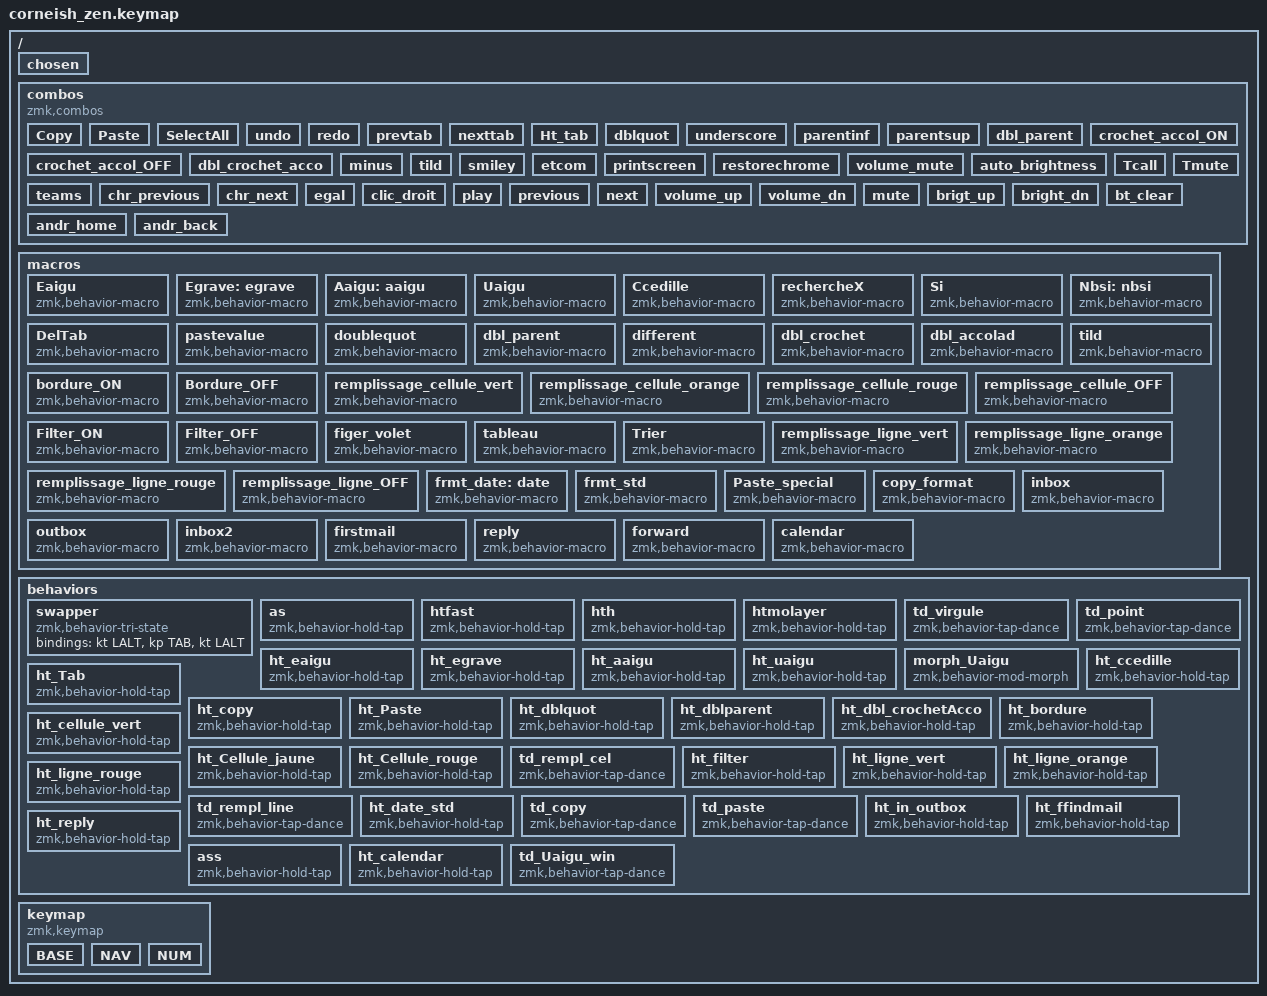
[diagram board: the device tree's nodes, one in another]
#include <behaviors.dtsi>
#include <dt-bindings/zmk/bt.h>
#include <dt-bindings/zmk/keys.h>

/ {
    chosen {
        zmk,physical-layout = &foostan_corne_6col_layout;

        // zmk,physical-layout = &foostan_corne_5col_layout;
    };
};

/ {
    combos {
        compatible = "zmk,combos";

        //-----------------------------------------------------------------
        //-----------------------------------------------------------------

        Copy {
            bindings = <&td_copy>;
            key-positions = <14 15>;
            timeout-ms = <20>;
        };

        Paste {
            bindings = <&td_paste>;
            key-positions = <15 16>;
            timeout-ms = <20>;
        };

        SelectAll {
            bindings = <&kp LC(Q)>;
            key-positions = <14 15 16>;
        };

        undo {
            bindings = <&kp LC(W)>;
            key-positions = <2 3>;
            timeout-ms = <20>;
        };

        redo {
            bindings = <&kp LC(Y)>;
            key-positions = <3 4>;
            timeout-ms = <20>;
        };

        prevtab {
            bindings = <&kp LC(PAGE_UP)>;
            key-positions = <26 27>;
            layers = <0 3>;
        };

        nexttab {
            bindings = <&kp LC(PAGE_DOWN)>;
            key-positions = <27 28>;
            layers = <0 3>;
        };

        Ht_tab {
            bindings = <&ht_Tab 0 LS(F11)>;
            key-positions = <26 27 28>;
            layers = <0>;
        };

        dblquot {
            bindings = <&ht_dblquot 0 N3>;
            key-positions = <16 17>;
        };

        underscore {
            bindings = <&kp N8>;
            key-positions = <28 29>;
        };

        parentinf {
            bindings = <&hth NUBS N5>;
            key-positions = <19 20>;
            timeout-ms = <15>;
        };

        parentsup {
            bindings = <&hth LS(NUBS) MINUS>;
            key-positions = <20 21>;
        };

        dbl_parent {
            bindings = <&ht_dblparent 0 0>;
            key-positions = <19 20 21>;
        };

        crochet_accol_ON {
            bindings = <&hth RA(N4) RA(N5)>;
            key-positions = <31 32>;
            layers = <0>;
        };

        crochet_accol_OFF {
            bindings = <&hth RA(EQUAL) RA(MINUS)>;
            key-positions = <32 33>;
        };

        dbl_crochet_acco {
            bindings = <&ht_dbl_crochetAcco 0 0>;
            key-positions = <31 32 33>;
            layers = <0>;
        };

        minus {
            bindings = <&kp N6>;
            key-positions = <18 19>;
        };

        tild {
            bindings = <&tild>;
            key-positions = <5 6>;
        };

        smiley {
            bindings = <&kp LG(COMMA)>;
            key-positions = <17 18>;
        };

        etcom {
            bindings = <&kp N1>;
            key-positions = <29 30>;
        };

        printscreen {
            bindings = <&hth LG(N9) LS(LG(S))>;
            key-positions = <4 5>;
        };

        restorechrome {
            bindings = <&kp LS(LC(T))>;
            key-positions = <26 27 28>;
            layers = <1 3>;
        };

        volume_mute {
            bindings = <&kp C_MUTE>;
            key-positions = <10 11>;
            layers = <1>;
        };

        auto_brightness {
            bindings = <&kp C_BRIGHTNESS_AUTO>;
            key-positions = <22 23>;
            layers = <1>;
        };

        Tcall {
            bindings = <&hth LC(LS(H)) LS(LC(S))>;
            key-positions = <38 39>;
        };

        Tmute {
            bindings = <&kp LS(LC(SEMI))>;
            key-positions = <40 37>;
        };

        teams {
            bindings = <&kp LG(N1)>;
            key-positions = <36 41>;
        };

        chr_previous {
            bindings = <&kp LA(LEFT)>;
            key-positions = <26 27>;
            layers = <1>;
        };

        chr_next {
            bindings = <&kp LA(RIGHT)>;
            key-positions = <28 27>;
            layers = <1>;
        };

        egal {
            bindings = <&kp EQUAL>;
            key-positions = <30 31>;
        };

        clic_droit {
            bindings = <&kp K_APP>;
            key-positions = <6 7>;
        };

        play {
            bindings = <&kp C_PLAY_PAUSE>;
            key-positions = <7 8 9>;
        };

        previous {
            bindings = <&kp C_PREVIOUS>;
            key-positions = <7 8>;
        };

        next {
            bindings = <&kp C_NEXT>;
            key-positions = <8 9>;
        };

        volume_up {
            bindings = <&kp C_VOLUME_UP>;
            key-positions = <11 23>;
            layers = <0>;
        };

        volume_dn {
            bindings = <&kp C_VOLUME_DOWN>;
            key-positions = <35 23>;
            layers = <0>;
        };

        mute {
            bindings = <&kp C_MUTE>;
            key-positions = <10 11>;
        };

        brigt_up {
            bindings = <&kp C_BRIGHTNESS_INC>;
            key-positions = <12 0>;
        };

        bright_dn {
            bindings = <&kp C_BRIGHTNESS_DEC>;
            key-positions = <12 24>;
        };

        bt_clear {
            bindings = <&bt BT_CLR>;
            key-positions = <22 23>;
            layers = <1>;
        };

        andr_home {
            bindings = <&kp LG(RET)>;
            key-positions = <31 32 33>;
            layers = <1>;
        };

        andr_back {
            bindings = <&kp LG(BACKSPACE)>;
            key-positions = <31>;
            layers = <1>;
        };
    };

    macros {
    //-----------------------------------------------------------------
    //-----------------------------------------------------------------

        Eaigu: Eaigu {
            compatible = "zmk,behavior-macro";
            #binding-cells = <0>;
            bindings =
                <&macro_press>,
                <&kp LEFT_ALT>,
                <&macro_tap>,
                <&kp KP_N1 &kp KP_N4 &kp KP_N4>,
                <&macro_release>,
                <&kp LEFT_ALT>;

            label = "EAIGU";
        };

        Egrave: egrave {
            compatible = "zmk,behavior-macro";
            #binding-cells = <0>;
            bindings =
                <&macro_press>,
                <&kp LEFT_ALT>,
                <&macro_tap>,
                <&kp KP_N2 &kp KP_N1 &kp KP_N2>,
                <&macro_release>,
                <&kp LEFT_ALT>;

            label = "EGRAVE";
        };

        Aaigu: aaigu {
            compatible = "zmk,behavior-macro";
            #binding-cells = <0>;
            bindings =
                <&macro_press>,
                <&kp LEFT_ALT>,
                <&macro_tap>,
                <&kp KP_N0 &kp KP_N1 &kp KP_N9 &kp KP_N2>,
                <&macro_release>,
                <&kp LEFT_ALT>;

            label = "AAIGU";
        };

        Uaigu: Uaigu {
            compatible = "zmk,behavior-macro";
            #binding-cells = <0>;
            bindings =
                <&macro_press>,
                <&kp LEFT_ALT>,
                <&macro_tap>,
                <&kp KP_N2 &kp KP_N3 &kp KP_N5>,
                <&macro_release>,
                <&kp LEFT_ALT>;

            label = "UAIGU";
        };

        Ccedille: Ccedille {
            compatible = "zmk,behavior-macro";
            #binding-cells = <0>;
            bindings =
                <&macro_press>,
                <&kp LEFT_ALT>,
                <&macro_tap>,
                <&kp KP_N1 &kp KP_N2 &kp KP_N8>,
                <&macro_release>,
                <&kp LEFT_ALT>;

            label = "CCEDILLE";
        };

        rechercheX: rechercheX {
            compatible = "zmk,behavior-macro";
            #binding-cells = <0>;
            bindings = <&kp DEL &kp F2 &kp MINUS &kp LEFT &kp EQUAL &kp LS(R) &kp LS(E) &kp LS(C) &kp LS(H) &kp LS(E) &kp LS(R) &kp LS(C) &kp LS(H) &kp LS(E) &kp LS(X) &kp N5>;
            label = "RECHERCHEX";
        };

        Si: Si {
            compatible = "zmk,behavior-macro";
            #binding-cells = <0>;
            bindings = <&kp DEL &kp F2 &kp MINUS &kp LEFT &kp EQUAL &kp LS(S) &kp LS(I) &kp N5>;
            label = "SI";
        };

        Nbsi: nbsi {
            compatible = "zmk,behavior-macro";
            #binding-cells = <0>;
            bindings = <&kp DEL &kp F2 &kp MINUS &kp LEFT &kp EQUAL &kp LS(N) &kp LS(B) &kp LS(COMMA) &kp LS(S) &kp LS(I) &kp N5>;
            label = "NBSI";
        };

        DelTab: DelTab {
            compatible = "zmk,behavior-macro";
            #binding-cells = <0>;
            bindings = <&kp LEFT_ALT &kp L &kp U &kp S &kp F>;
            label = "DELTAB";
        };

        pastevalue: pastevalue {
            compatible = "zmk,behavior-macro";
            #binding-cells = <0>;
            bindings = <&kp LA(LC(V)) &kp V &kp RET>;
            label = "PASTEVALUE";
        };

        doublequot: doublequot {
            compatible = "zmk,behavior-macro";
            #binding-cells = <0>;
            bindings = <&kp N3 &kp N3 &kp LEFT>;
            label = "DOUBLEQUOT";
        };

        dbl_parent: dbl_parent {
            compatible = "zmk,behavior-macro";
            #binding-cells = <0>;
            bindings = <&kp N5 &kp MINUS &kp LEFT>;
            label = "DBL_PARENT";
        };

        different: different {
            compatible = "zmk,behavior-macro";
            #binding-cells = <0>;
            bindings = <&kp NUBS &kp LS(NUBS) &kp SPACE>;
            label = "DIFFERENT";
        };

        dbl_crochet: dbl_crochet {
            compatible = "zmk,behavior-macro";
            #binding-cells = <0>;
            bindings = <&kp RA(N5) &kp RA(MINUS) &kp LEFT>;
            label = "DBL_CROCHET";
        };

        dbl_accolad: dbl_accolad {
            compatible = "zmk,behavior-macro";
            #binding-cells = <0>;
            bindings = <&kp RA(N4) &kp RA(EQUAL) &kp LEFT>;
            label = "DBL_ACCOLAD";
        };

        tild: tild {
            compatible = "zmk,behavior-macro";
            #binding-cells = <0>;
            bindings = <&kp RA(N7) &kp SPACE>;
            label = "TILD";
        };

        bordure_ON: bordure_ON {
            compatible = "zmk,behavior-macro";
            #binding-cells = <0>;
            bindings = <&kp LC(Q) &kp LEFT_ALT &kp L &kp N9 &kp J &kp LEFT_ALT &kp L &kp N9 &kp Q &kp LEFT_ALT &kp L &kp B &kp B &kp E>;
            label = "BORDURE_ON";
        };

        Bordure_OFF: Bordure_OFF {
            compatible = "zmk,behavior-macro";
            #binding-cells = <0>;
            bindings = <&kp LEFT_ALT &kp L &kp B &kp B &kp U>;
            label = "BORDURE_OFF";
        };

        remplissage_cellule_vert: remplissage_cellule_vert {
            compatible = "zmk,behavior-macro";
            #binding-cells = <0>;
            wait-ms = <10>;
            tap-ms = <5>;
            bindings = <&kp LEFT_ALT &kp L &kp T &kp T &kp HOME &kp RIGHT &kp RIGHT &kp RIGHT &kp ENTER>;
            label = "REMPLISSAGE_CELLULE_VERT";
        };

        remplissage_cellule_orange: remplissage_cellule_orange {
            compatible = "zmk,behavior-macro";
            #binding-cells = <0>;
            wait-ms = <10>;
            tap-ms = <5>;
            bindings = <&kp LEFT_ALT &kp L &kp T &kp T &kp HOME &kp RIGHT &kp RIGHT &kp ENTER>;
            label = "REMPLISSAGE_CELLULE_ORANGE";
        };

        remplissage_cellule_rouge: remplissage_cellule_rouge {
            compatible = "zmk,behavior-macro";
            #binding-cells = <0>;
            wait-ms = <10>;
            tap-ms = <5>;
            bindings = <&kp LEFT_ALT &kp L &kp T &kp T &kp HOME &kp RIGHT &kp ENTER>;
            label = "REMPLISSAGE_CELLULE_ROUGE";
        };

        remplissage_cellule_OFF: remplissage_cellule_OFF {
            compatible = "zmk,behavior-macro";
            #binding-cells = <0>;
            bindings = <&kp LEFT_ALT &kp L &kp H &kp LS(N1) &kp N &kp LEFT_ALT &kp L &kp G &kp O &kp ENTER>;
            label = "REMPLISSAGE_CELLULE_OFF";
        };

        Filter_ON: Filter_ON {
            compatible = "zmk,behavior-macro";
            #binding-cells = <0>;
            bindings = <&kp DOWN &kp DOWN_ARROW &kp LC(SPACE) &kp LC(M) &kp RIGHT &kp LEFT_ARROW &kp LA(DOWN_ARROW) &kp DOWN &kp DOWN_ARROW &kp DOWN_ARROW &kp DOWN_ARROW &kp DOWN_ARROW &kp DOWN_ARROW &kp DOWN_ARROW &kp DOWN_ARROW>;
            label = "FILTER_ON";
        };

        Filter_OFF: Filter_OFF {
            compatible = "zmk,behavior-macro";
            #binding-cells = <0>;
            bindings = <&kp DOWN &kp DOWN_ARROW &kp LC(SPACE) &kp LC(M) &kp RIGHT &kp LEFT_ARROW &kp LA(DOWN_ARROW) &kp DOWN &kp DOWN_ARROW &kp DOWN_ARROW &kp DOWN_ARROW &kp DOWN_ARROW &kp RET>;
            label = "FILTER_OFF";
        };

        figer_volet: figer_volet {
            compatible = "zmk,behavior-macro";
            #binding-cells = <0>;
            bindings = <&kp LEFT_ALT &kp N &kp N0 &kp R &kp LEFT_ALT &kp L &kp R &kp F>;
            label = "FIGER_VOLET";
        };

        tableau: tableau {
            compatible = "zmk,behavior-macro";
            #binding-cells = <0>;
            bindings =
                <&kp LC(Q) &kp LC(L)>,
                <&macro_wait_time 100>,
                <&kp ENTER>,
                <&macro_wait_time 500>,
                <&kp LEFT_ALT &kp J &kp T>,
                <&macro_wait_time 10>,
                <&kp T>,
                <&macro_wait_time 100>,
                <&kp PG_UP &kp ENTER>;

            label = "TABLEAU";
        };

        Trier: Trier {
            compatible = "zmk,behavior-macro";
            #binding-cells = <0>;
            bindings =
                <&kp LEFT_ALT &kp L &kp R &kp T>,
                <&macro_wait_time 200>,
                <&kp LS(TAB) &kp LS(TAB) &kp TAB &kp TAB &kp DOWN>;

            label = "TRIER";
        };

        remplissage_ligne_vert: remplissage_ligne_vert {
            compatible = "zmk,behavior-macro";
            #binding-cells = <0>;
            wait-ms = <10>;
            tap-ms = <5>;
            bindings = <&kp LS(SPACE) &kp LEFT_ALT &kp L &kp T &kp T &kp HOME &kp RIGHT &kp RIGHT &kp RIGHT &kp ENTER>;
            label = "REMPLISSAGE_LIGNE_VERT";
        };

        remplissage_ligne_orange: remplissage_ligne_orange {
            compatible = "zmk,behavior-macro";
            #binding-cells = <0>;
            wait-ms = <10>;
            tap-ms = <5>;
            bindings = <&kp LS(SPACE) &kp LEFT_ALT &kp L &kp T &kp T &kp HOME &kp RIGHT &kp RIGHT &kp ENTER>;
            label = "REMPLISSAGE_LIGNE_ORANGE";
        };

        remplissage_ligne_rouge: remplissage_ligne_rouge {
            compatible = "zmk,behavior-macro";
            #binding-cells = <0>;
            wait-ms = <10>;
            tap-ms = <5>;
            bindings = <&kp LS(SPACE) &kp LEFT_ALT &kp L &kp T &kp T &kp HOME &kp RIGHT &kp ENTER>;
            label = "REMPLISSAGE_LIGNE_ROUGE";
        };

        remplissage_ligne_OFF: remplissage_ligne_OFF {
            compatible = "zmk,behavior-macro";
            #binding-cells = <0>;
            bindings = <&kp LS(SPACE) &kp LEFT_ALT &kp L &kp H &kp LS(N1) &kp N &kp LEFT_ALT &kp L &kp G &kp O &kp ENTER>;
            label = "REMPLISSAGE_LIGNE_OFF";
        };

        frmt_date: date {
            compatible = "zmk,behavior-macro";
            #binding-cells = <0>;
            bindings = <&kp LS(LC(N1)) &kp N &kp TAB &kp HOME &kp DOWN_ARROW &kp DOWN_ARROW &kp DOWN_ARROW &kp DOWN_ARROW &kp ENTER>;
            label = "DATE";
        };

        frmt_std: frmt_std {
            compatible = "zmk,behavior-macro";
            #binding-cells = <0>;
            bindings = <&kp LS(LC(N1)) &kp N &kp TAB &kp HOME &kp ENTER>;
            label = "FRMT_STD";
        };

        Paste_special: Paste_special {
            compatible = "zmk,behavior-macro";
            #binding-cells = <0>;
            bindings = <&kp LEFT_ALT &kp L &kp V &kp G>;
            label = "PASTE_SPECIAL";
        };

        copy_format: copy_format {
            compatible = "zmk,behavior-macro";
            #binding-cells = <0>;
            bindings = <&kp LEFT_ALT &kp L &kp Z &kp R>;
            label = "COPY_FORMAT";
        };

        inbox: inbox {
            compatible = "zmk,behavior-macro";
            #binding-cells = <0>;
            bindings =
                <&kt LEFT_GUI &kp N2 &kt LEFT_GUI>,
                <&macro_wait_time 100>,
                <&kp RET>,
                <&macro_wait_time 650>,
                <&kp F3>,
                <&macro_wait_time 100>,
                <&kp ESC &kp ESC &kp LC(LS(TAB)) &kp HOME &kp HOME &kp HOME &kp DOWN &kp DOWN &kp SPACE &kp F3 &kp ESC &kp ESC &kp LC(HOME)>;

            label = "INBOX";
            wait-ms = <15>;
            tap-ms = <10>;
        };

        outbox: outbox {
            compatible = "zmk,behavior-macro";
            #binding-cells = <0>;
            bindings = <&kp F3 &kp ESC &kp ESC &kp LC(LS(TAB)) &kp HOME &kp HOME &kp HOME &kp DOWN &kp DOWN &kp DOWN &kp SPACE>;
            label = "OUTBOX";
            wait-ms = <10>;
            tap-ms = <5>;
        };

        inbox2: inbox2 {
            compatible = "zmk,behavior-macro";
            #binding-cells = <0>;
            bindings =
                <&kp F3>,
                <&macro_wait_time 50>,
                <&kp ESC &kp ESC &kp LC(LS(TAB)) &kp HOME &kp HOME &kp HOME &kp DOWN &kp DOWN &kp SPACE &kp F3 &kp ESC &kp ESC &kp LC(HOME)>;

            label = "INBOX2";
            wait-ms = <10>;
            tap-ms = <5>;
        };

        firstmail: firstmail {
            compatible = "zmk,behavior-macro";
            #binding-cells = <0>;
            bindings = <&kp F3 &kp ESC &kp ESC &kp LC(HOME)>;
            label = "FIRSTMAIL";
            wait-ms = <10>;
            tap-ms = <10>;
        };

        reply: reply {
            compatible = "zmk,behavior-macro";
            #binding-cells = <0>;
            bindings = <&kp LS(LC(R)) &kp LC(O)>;
            label = "REPLY";
        };

        forward: forward {
            compatible = "zmk,behavior-macro";
            #binding-cells = <0>;
            bindings = <&kp LC(F) &kp LC(O)>;
            label = "FORWARD";
        };

        calendar: calendar {
            compatible = "zmk,behavior-macro";
            #binding-cells = <0>;
            bindings =
                <&kt LEFT_GUI &kp N2 &kt LEFT_GUI>,
                <&macro_wait_time 100>,
                <&kp RET>,
                <&macro_wait_time 650>,
                <&kp LC(N2)>;

            label = "CALENDAR";
            wait-ms = <15>;
            tap-ms = <10>;
        };
    };

    //-----------------------------------------------------------------
    behaviors {
        swapper: swapper {
            compatible = "zmk,behavior-tri-state";
            #binding-cells = <0>;
            bindings = <&kt LALT>, <&kp TAB>, <&kt LALT>;
        };
    };

    behaviors {
        as: as {
            compatible = "zmk,behavior-hold-tap";
            label = "AutoShift";
            bindings = <&kp>, <&kp>;

            #binding-cells = <2>;
            tapping-term-ms = <150>;
            flavor = "tap-preferred";
        };

        htfast: htfast {
            compatible = "zmk,behavior-hold-tap";
            label = "HoldTap_Fast";
            bindings = <&kp>, <&kp>;

            #binding-cells = <2>;
            tapping-term-ms = <135>;
            quick-tap-ms = <100>;
            flavor = "tap-preferred";
        };

        hth: hth {
            compatible = "zmk,behavior-hold-tap";
            label = "HoldTapHold";
            bindings = <&kp>, <&kp>;

            #binding-cells = <2>;
            tapping-term-ms = <135>;
        };

        htmolayer: htmolayer {
            compatible = "zmk,behavior-hold-tap";
            label = "HTMOLAYER";
            bindings = <&mo>, <&kp>;

            #binding-cells = <2>;
            tapping-term-ms = <130>;
            flavor = "tap-preferred";
            hold-while-undecided;
        };

        td_virgule: td_virgule {
            compatible = "zmk,behavior-tap-dance";
            label = "TD_VIRGULE";
            #binding-cells = <0>;
            bindings = <&hth COMMA M>, <&kp DOT>;

            tapping-term-ms = <220>;
        };

        td_point: td_point {
            compatible = "zmk,behavior-tap-dance";
            label = "TD_POINT";
            #binding-cells = <0>;
            bindings = <&hth LS(M) LS(COMMA)>, <&kp SLASH>;

            tapping-term-ms = <220>;
        };

        ht_eaigu: ht_eaigu {
            compatible = "zmk,behavior-hold-tap";
            label = "HT_EAIGU";
            bindings = <&Eaigu>, <&kp>;

            #binding-cells = <2>;
            tapping-term-ms = <150>;
            flavor = "tap-preferred";
        };

        ht_egrave: ht_egrave {
            compatible = "zmk,behavior-hold-tap";
            label = "HT_EGRAVE";
            bindings = <&Egrave>, <&kp>;

            #binding-cells = <2>;
            tapping-term-ms = <150>;
            flavor = "tap-preferred";
        };

        ht_aaigu: ht_aaigu {
            compatible = "zmk,behavior-hold-tap";
            label = "HT_AAIGU";
            bindings = <&Aaigu>, <&kp>;

            #binding-cells = <2>;
            tapping-term-ms = <150>;
            flavor = "tap-preferred";
        };

        ht_uaigu: ht_uaigu {
            compatible = "zmk,behavior-hold-tap";
            label = "HT_UAIGU";
            bindings = <&Uaigu>, <&kp>;

            #binding-cells = <2>;
            tapping-term-ms = <160>;
            flavor = "tap-preferred";
        };

        morph_Uaigu: morph_Uaigu {
            compatible = "zmk,behavior-mod-morph";
            label = "MORPH_UAIGU";
            bindings = <&ht_uaigu 0 SQT>, <&hth LA(F4) LC(Z)>;

            #binding-cells = <0>;
            mods = <(MOD_LCTL)>;
        };

        ht_ccedille: ht_ccedille {
            compatible = "zmk,behavior-hold-tap";
            label = "HT_CCEDILLE";
            bindings = <&Ccedille>, <&kp>;

            #binding-cells = <2>;
            tapping-term-ms = <150>;
            flavor = "tap-preferred";
        };

        ht_Tab: ht_Tab {
            compatible = "zmk,behavior-hold-tap";
            label = "HT_TAB";
            bindings = <&DelTab>, <&kp>;

            #binding-cells = <2>;
            tapping-term-ms = <150>;
        };

        ht_copy: ht_copy {
            compatible = "zmk,behavior-hold-tap";
            label = "HT_COPY";
            bindings = <&kp>, <&kp>;

            #binding-cells = <2>;
            tapping-term-ms = <220>;
        };

        ht_Paste: ht_Paste {
            compatible = "zmk,behavior-hold-tap";
            label = "HT_PASTE";
            bindings = <&Paste_special>, <&kp>;

            #binding-cells = <2>;
            tapping-term-ms = <220>;
        };

        ht_dblquot: ht_dblquot {
            compatible = "zmk,behavior-hold-tap";
            label = "HT_DBLQUOT";
            bindings = <&doublequot>, <&kp>;

            #binding-cells = <2>;
            tapping-term-ms = <220>;
        };

        ht_dblparent: ht_dblparent {
            compatible = "zmk,behavior-hold-tap";
            label = "HT_DBLPARENT";
            bindings = <&different>, <&dbl_parent>;

            #binding-cells = <2>;
            tapping-term-ms = <100>;
        };

        ht_dbl_crochetAcco: ht_dbl_crochetAcco {
            compatible = "zmk,behavior-hold-tap";
            label = "HT_DBL_CROCHETACCO";
            bindings = <&dbl_accolad>, <&dbl_crochet>;

            #binding-cells = <2>;
            tapping-term-ms = <100>;
        };

        ht_bordure: ht_bordure {
            compatible = "zmk,behavior-hold-tap";
            label = "HT_BORDURE";
            bindings = <&Bordure_OFF>, <&bordure_ON>;

            #binding-cells = <2>;
            tapping-term-ms = <180>;
        };

        ht_cellule_vert: ht_cellule_vert {
            compatible = "zmk,behavior-hold-tap";
            label = "HT_CELLULE_VERT";
            bindings = <&remplissage_cellule_OFF>, <&remplissage_cellule_vert>;

            #binding-cells = <2>;
            tapping-term-ms = <180>;
        };

        ht_Cellule_jaune: ht_Cellule_jaune {
            compatible = "zmk,behavior-hold-tap";
            label = "HT_CELLULE_JAUNE";
            bindings =
                <&remplissage_cellule_OFF>,
                <&remplissage_cellule_orange>;

            #binding-cells = <2>;
            tapping-term-ms = <180>;
        };

        ht_Cellule_rouge: ht_Cellule_rouge {
            compatible = "zmk,behavior-hold-tap";
            label = "HT_CELLULE_ROUGE";
            bindings = <&remplissage_cellule_OFF>, <&remplissage_cellule_rouge>;

            #binding-cells = <2>;
            tapping-term-ms = <180>;
        };

        td_rempl_cel: td_rempl_cel {
            compatible = "zmk,behavior-tap-dance";
            label = "TD_REMPL_CEL";
            #binding-cells = <0>;
            bindings =
                <&ht_cellule_vert 0 0>,
                <&ht_Cellule_jaune 0 0>,
                <&ht_Cellule_rouge 0 0>;

            tapping-term-ms = <250>;
        };

        ht_filter: ht_filter {
            compatible = "zmk,behavior-hold-tap";
            label = "HT_FILTER";
            bindings = <&Filter_OFF>, <&Filter_ON>;

            #binding-cells = <2>;
            tapping-term-ms = <150>;
        };

        ht_ligne_vert: ht_ligne_vert {
            compatible = "zmk,behavior-hold-tap";
            label = "HT_LIGNE_VERT";
            bindings = <&remplissage_ligne_OFF>, <&remplissage_ligne_vert>;

            #binding-cells = <2>;
            tapping-term-ms = <180>;
        };

        ht_ligne_orange: ht_ligne_orange {
            compatible = "zmk,behavior-hold-tap";
            label = "HT_LIGNE_ORANGE";
            bindings = <&remplissage_ligne_OFF>, <&remplissage_ligne_orange>;

            #binding-cells = <2>;
            tapping-term-ms = <180>;
        };

        ht_ligne_rouge: ht_ligne_rouge {
            compatible = "zmk,behavior-hold-tap";
            label = "HT_LIGNE_ROUGE";
            bindings = <&remplissage_ligne_OFF>, <&remplissage_ligne_rouge>;

            #binding-cells = <2>;
            tapping-term-ms = <180>;
        };

        td_rempl_line: td_rempl_line {
            compatible = "zmk,behavior-tap-dance";
            label = "TD_REMPL_LINE";
            #binding-cells = <0>;
            bindings =
                <&ht_ligne_vert 0 0>,
                <&ht_ligne_orange 0 0>,
                <&ht_ligne_rouge 0 0>;

            tapping-term-ms = <250>;
        };

        ht_date_std: ht_date_std {
            compatible = "zmk,behavior-hold-tap";
            label = "HT_DATE_STD";
            bindings = <&frmt_std>, <&frmt_date>;

            #binding-cells = <2>;
            tapping-term-ms = <150>;
        };

        td_copy: td_copy {
            compatible = "zmk,behavior-tap-dance";
            label = "TD_COPY";
            #binding-cells = <0>;
            bindings = <&ht_copy LC(X) LC(C)>, <&copy_format>;

            tapping-term-ms = <220>;
        };

        td_paste: td_paste {
            compatible = "zmk,behavior-tap-dance";
            label = "TD_PASTE";
            #binding-cells = <0>;
            bindings = <&ht_Paste 0 LC(V)>, <&pastevalue>;

            tapping-term-ms = <220>;
        };

        ht_in_outbox: ht_in_outbox {
            compatible = "zmk,behavior-hold-tap";
            label = "HT_IN_OUTBOX";
            bindings = <&inbox2>, <&outbox>;

            #binding-cells = <2>;
            tapping-term-ms = <150>;
        };

        ht_ffindmail: ht_ffindmail {
            compatible = "zmk,behavior-hold-tap";
            label = "HT_FINDMAIL";
            bindings = <&kp>, <&firstmail>;

            #binding-cells = <2>;
            tapping-term-ms = <150>;
        };

        ht_reply: ht_reply {
            compatible = "zmk,behavior-hold-tap";
            label = "HT_REPLY";
            bindings = <&forward>, <&reply>;

            #binding-cells = <2>;
            tapping-term-ms = <150>;
        };

        ass: ass {
            compatible = "zmk,behavior-hold-tap";
            label = "AutoShift slow";
            bindings = <&kp>, <&kp>;

            #binding-cells = <2>;
            tapping-term-ms = <160>;
            flavor = "tap-preferred";
        };

        ht_calendar: ht_calendar {
            compatible = "zmk,behavior-hold-tap";
            label = "HT_CALENDAR";
            bindings = <&kp>, <&calendar>;

            #binding-cells = <2>;
            tapping-term-ms = <150>;
        };

        td_Uaigu_win: td_Uaigu_win {
            compatible = "zmk,behavior-tap-dance";
            label = "TD_UAIGU_WIN";
            #binding-cells = <0>;
            bindings = <&morph_Uaigu>, <&kp LEFT_GUI>;
        };
    };

    keymap {
        compatible = "zmk,keymap";

        BASE {
            display-name = "BASE";
            bindings = <
            &htfast RA(N3) RA(N0)  &as LS(B) B  &ht_eaigu 0 N2  &as LS(P) P  &as LS(O) O  &ht_egrave 0 N7  &as LS(LBKT) LBKT  &as LS(V) V  &as LS(D) D  &as LS(L) L  &as LS(J) J  &as LS(Z) Z  &ht_aaigu 0 N0  &ass LS(Q) Q  &ass LS(U) U  &as LS(I) I  &as LS(E) E  &htfast LS(MINUS) N4  &as LS(C) C  &as LS(T) T  &as LS(S) S  &as LS(R) R  &as LS(N) N  &as LS(SEMI) SEMI  &td_Uaigu_win  &as LS(X) X  &as LS(W) W  &as LS(Y) Y  &td_virgule  &td_point  &ht_ccedille 0 N9  &as LS(A) A  &as LS(G) G  &as LS(H) H  &as LS(F) F  &as LS(K) K  &htmolayer 2 ESC  &htmolayer 1 TAB  &hth LCTRL ENTER  &htmolayer 2 ENTER  &htmolayer 1 SPACE  &htfast LC(BACKSPACE) BACKSPACE

            >;
        };

        NAV {
            display-name = "NAV";
            bindings = <
            &inbox  &ht_ffindmail F3 0  &figer_volet  &ht_filter 0 0  &Trier  &tableau  &kp PG_UP  &kp HOME  &kp UP  &kp END  &bt BT_SEL 0  &bt BT_SEL 1  &ht_in_outbox 0 0  &ht_reply 0 0  &swapper  &Si  &rechercheX  &Nbsi  &kp PG_DN  &kp LEFT  &kp DOWN  &kp RIGHT  &bt BT_SEL 2  &bt BT_SEL 3  &kp LEFT_GUI  &ht_calendar LC(NUMBER_1) 0  &ht_date_std 0 0  &ht_bordure 0 0  &td_rempl_cel  &td_rempl_line  &kp LG(N3)  &kp LG(N4)  &kp LG(N5)  &kp LG(N6)  &kp LG(N7)  &kp LG(N8)  &kp LEFT_ALT  &hth LSHIFT LS(TAB)  &hth LCTRL ENTER  &kp LA(RET)  &kp RSHFT  &htfast LC(DELETE) DELETE

            >;
        };

        NUM {
            display-name = "NUM";
            bindings = <
            &kp LC(N3)  &none  &kp F7  &kp F8  &kp F9  &kp F12  &hth RA(N8) LS(DOT)  &kp LS(N7)  &kp LS(N8)  &kp LS(N9)  &kp RBKT  &kp KP_NUM  &kp LC(N2)  &none  &kp F4  &kp F5  &kp F6  &kp F11  &kp KP_MULTIPLY  &kp LS(N4)  &kp LS(N5)  &kp LS(N6)  &kp RA(E)  &kp LC(PAUSE_BREAK)  &kp LC(N5)  &kp LC(N4)  &kp F1  &kp F2  &kp F3  &kp F10  &kp LS(EQUAL)  &kp LS(N1)  &kp LS(N2)  &kp LS(N3)  &kp LS(SQT)  &kp LC(LA(DELETE))  &kp LEFT_ALT  &hth LEFT_SHIFT LS(TAB)  &hth LCTRL ENTER  &trans  &kp KP_DOT  &kp LS(N0)
  
            >;
        };
    };
};
